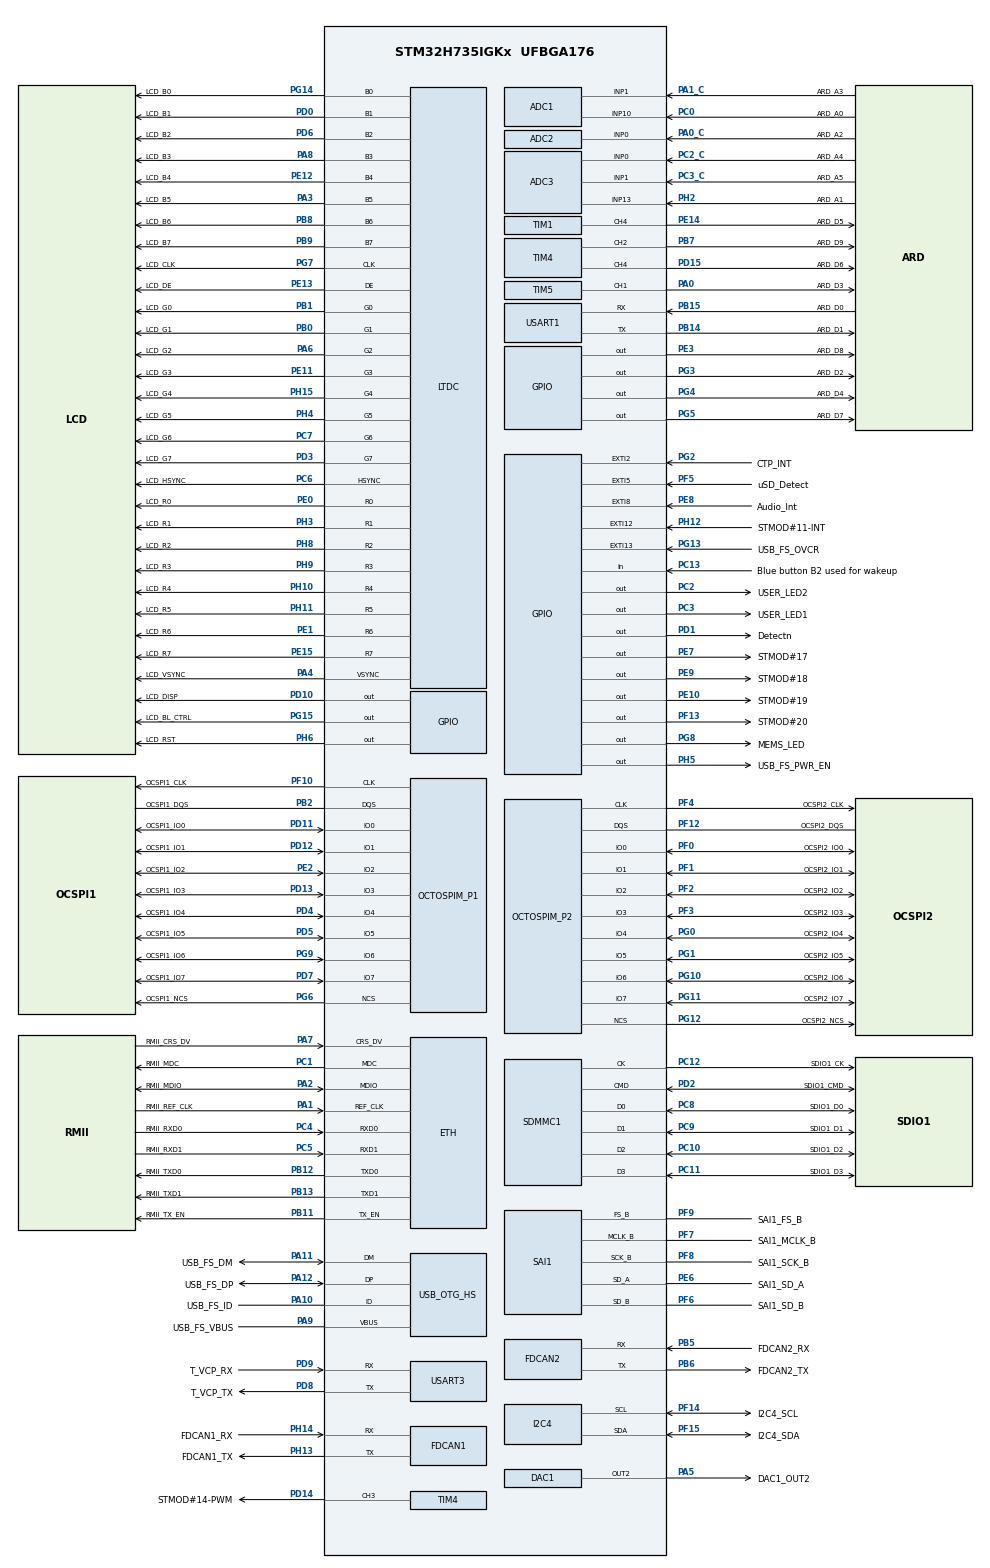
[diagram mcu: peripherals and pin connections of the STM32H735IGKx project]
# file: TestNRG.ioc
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ADC1.Channel-1\#ChannelRegularConversion=ADC_CHANNEL_1
ADC1.NbrOfConversionFlag=1
ADC1.OffsetNumber-1\#ChannelRegularConversion=ADC_OFFSET_NONE
ADC1.OffsetSignedSaturation-1\#ChannelRegularConversion=DISABLE
ADC1.Rank-1\#ChannelRegularConversion=1
ADC1.SamplingTime-1\#ChannelRegularConversion=ADC_SAMPLETIME_1CYCLE_5
ADC1.master=1
ADC2.Channel-0\#ChannelRegularConversion=ADC_CHANNEL_0
ADC2.NbrOfConversionFlag=1
ADC2.OffsetNumber-0\#ChannelRegularConversion=ADC_OFFSET_NONE
ADC2.OffsetSignedSaturation-0\#ChannelRegularConversion=DISABLE
ADC2.Rank-0\#ChannelRegularConversion=1
ADC2.SamplingTime-0\#ChannelRegularConversion=ADC_SAMPLETIME_1CYCLE_5
ADC3.Channel-2\#ChannelRegularConversion=ADC_CHANNEL_0
ADC3.NbrOfConversionFlag=1
ADC3.OffsetNumber-2\#ChannelRegularConversion=ADC_OFFSET_NONE
ADC3.OffsetSaturation-2\#ChannelRegularConversion=DISABLE
ADC3.OffsetSign-2\#ChannelRegularConversion=ADC3_OFFSET_SIGN_NEGATIVE
ADC3.OffsetSignedSaturation-2\#ChannelRegularConversion=DISABLE
ADC3.Rank-2\#ChannelRegularConversion=1
ADC3.SamplingTime-2\#ChannelRegularConversion=ADC3_SAMPLETIME_2CYCLES_5
DAC1.DAC_Channel-DAC_OUT2=DAC_CHANNEL_2
ETH.MediaInterface=HAL_ETH_RMII_MODE
FDCAN1.CalculateBaudRateNominal=1718750
FDCAN1.CalculateTimeBitNominal=581
FDCAN1.CalculateTimeQuantumNominal=116.36363636363636
FDCAN2.CalculateBaudRateNominal=1718750
FDCAN2.CalculateTimeBitNominal=581
FDCAN2.CalculateTimeQuantumNominal=116.36363636363636
I2C4.Timing=0x60404E72
Mcu.Family=STM32H7
Mcu.Name=STM32H735IGKx
Mcu.Package=UFBGA176
NVIC.PriorityGroup=NVIC_PRIORITYGROUP_4
PA0.GPIO_Label=ARD_D3
PA0.Signal=S_TIM5_CH1
PA0_C.GPIO_Label=ARD_A2
PA0_C.Signal=ADCx_INP0
PA1.GPIO_Label=RMII_REF_CLK
PA1.GPIO_Speed=GPIO_SPEED_FREQ_LOW
PA1.Mode=RMII
PA1.Signal=ETH_REF_CLK
PA10.GPIO_Label=USB_FS_ID
PA10.Mode=OTG/Dual-Role-Device-FS
PA10.Signal=USB_OTG_HS_ID
PA11.GPIO_Label=USB_FS_DM
PA11.Mode=OTG/Dual-Role-Device-FS
PA11.Signal=USB_OTG_HS_DM
PA12.GPIO_Label=USB_FS_DP
PA12.Mode=OTG/Dual-Role-Device-FS
PA12.Signal=USB_OTG_HS_DP
PA13(JTMS/SWDIO).GPIO_Label=JTMS
PA13(JTMS/SWDIO).Mode=JTAG_5_pins
PA13(JTMS/SWDIO).Signal=DEBUG_JTMS-SWDIO
PA14(JTCK/SWCLK).GPIO_Label=JTCK
PA14(JTCK/SWCLK).Mode=JTAG_5_pins
PA14(JTCK/SWCLK).Signal=DEBUG_JTCK-SWCLK
PA15(JTDI).GPIO_Label=JTDI
PA15(JTDI).Mode=JTAG_5_pins
PA15(JTDI).Signal=DEBUG_JTDI
PA1_C.GPIO_Label=ARD_A3
PA1_C.Signal=ADCx_INP1
PA2.GPIO_Label=RMII_MDIO
PA2.GPIO_Speed=GPIO_SPEED_FREQ_LOW
PA2.Mode=RMII
PA2.Signal=ETH_MDIO
PA3.GPIO_Label=LCD_B5
PA3.GPIO_Speed=GPIO_SPEED_FREQ_LOW
PA3.Mode=RGB888
PA3.Signal=LTDC_B5
PA4.GPIO_Label=LCD_VSYNC
PA4.GPIO_Speed=GPIO_SPEED_FREQ_LOW
PA4.Mode=RGB888
PA4.Signal=LTDC_VSYNC
PA5.GPIO_Label=DAC1_OUT2
PA5.Signal=COMP_DAC12_group
PA6.GPIO_Label=LCD_G2
PA6.GPIO_Speed=GPIO_SPEED_FREQ_LOW
PA6.Mode=RGB888
PA6.Signal=LTDC_G2
PA7.GPIO_Label=RMII_CRS_DV
PA7.GPIO_Speed=GPIO_SPEED_FREQ_LOW
PA7.Mode=RMII
PA7.Signal=ETH_CRS_DV
PA8.GPIO_Label=LCD_B3
PA8.GPIO_Speed=GPIO_SPEED_FREQ_LOW
PA8.Mode=RGB888
PA8.Signal=LTDC_B3
PA9.GPIO_Label=USB_FS_VBUS
PA9.Mode=Activate_VBUS_FS
PA9.Signal=USB_OTG_HS_VBUS
PB0.GPIO_Label=LCD_G1
PB0.GPIO_Speed=GPIO_SPEED_FREQ_LOW
PB0.Mode=RGB888
PB0.Signal=LTDC_G1
PB1.GPIO_Label=LCD_G0
PB1.GPIO_Speed=GPIO_SPEED_FREQ_LOW
PB1.Mode=RGB888
PB1.Signal=LTDC_G0
PB10.GPIO_Label=RMII_RX_ER
PB10.Signal=ETH_RX_ER
PB11.GPIO_Label=RMII_TX_EN
PB11.GPIO_Speed=GPIO_SPEED_FREQ_LOW
PB11.Mode=RMII
PB11.Signal=ETH_TX_EN
PB12.GPIO_Label=RMII_TXD0
PB12.GPIO_Speed=GPIO_SPEED_FREQ_LOW
PB12.Mode=RMII
PB12.Signal=ETH_TXD0
PB13.GPIO_Label=RMII_TXD1
PB13.GPIO_Speed=GPIO_SPEED_FREQ_LOW
PB13.Mode=RMII
PB13.Signal=ETH_TXD1
PB14.GPIO_Label=ARD_D1
PB14.GPIO_PuPd=GPIO_NOPULL
PB14.Mode=Asynchronous
PB14.Signal=USART1_TX
PB15.GPIO_Label=ARD_D0
PB15.GPIO_PuPd=GPIO_NOPULL
PB15.Mode=Asynchronous
PB15.Signal=USART1_RX
PB2.GPIO_Label=OCSPI1_DQS
PB2.Mode=OCTOSPI1_Port1_DQS
PB2.Signal=OCTOSPIM_P1_DQS
PB3(JTDO/TRACESWO).GPIO_Label=JTDO
PB3(JTDO/TRACESWO).Mode=JTAG_5_pins
PB3(JTDO/TRACESWO).Signal=DEBUG_JTDO-SWO
PB4(NJTRST).GPIO_Label=NJTRST
PB4(NJTRST).Mode=JTAG_5_pins
PB4(NJTRST).Signal=DEBUG_JTRST
PB5.GPIO_Label=FDCAN2_RX
PB5.Mode=FDCAN_Activate
PB5.Signal=FDCAN2_RX
PB6.GPIO_Label=FDCAN2_TX
PB6.Mode=FDCAN_Activate
PB6.Signal=FDCAN2_TX
PB7.GPIO_Label=ARD_D9
PB7.Signal=S_TIM4_CH2
PB8.GPIO_Label=LCD_B6
PB8.GPIO_Speed=GPIO_SPEED_FREQ_LOW
PB8.Mode=RGB888
PB8.Signal=LTDC_B6
PB9.GPIO_Label=LCD_B7
PB9.GPIO_Speed=GPIO_SPEED_FREQ_LOW
PB9.Mode=RGB888
PB9.Signal=LTDC_B7
PC0.GPIO_Label=ARD_A0
PC0.Signal=ADCx_INP10
PC1.GPIO_Label=RMII_MDC
PC1.GPIO_Speed=GPIO_SPEED_FREQ_LOW
PC1.Mode=RMII
PC1.Signal=ETH_MDC
PC10.GPIO_Label=SDIO1_D2
PC10.Mode=SD_4_bits_Wide_bus
PC10.Signal=SDMMC1_D2
PC11.GPIO_Label=SDIO1_D3
PC11.Mode=SD_4_bits_Wide_bus
PC11.Signal=SDMMC1_D3
PC12.GPIO_Label=SDIO1_CK
PC12.Mode=SD_4_bits_Wide_bus
PC12.Signal=SDMMC1_CK
PC13.GPIO_Label=Blue button B2 used for wakeup
PC13.Signal=GPIO_Input
PC14-OSC32_IN.Mode=LSE-External-Oscillator
PC14-OSC32_IN.Signal=RCC_OSC32_IN
PC15-OSC32_OUT.Mode=LSE-External-Oscillator
PC15-OSC32_OUT.Signal=RCC_OSC32_OUT
PC2.GPIO_Label=USER_LED2
PC2.Signal=GPIO_Output
PC2_C.GPIO_Label=ARD_A4
PC2_C.Mode=IN0-Single-Ended
PC2_C.Signal=ADC3_INP0
PC3.GPIO_Label=USER_LED1
PC3.Signal=GPIO_Output
PC3_C.GPIO_Label=ARD_A5
PC3_C.Mode=IN1-Single-Ended
PC3_C.Signal=ADC3_INP1
PC4.GPIO_Label=RMII_RXD0
PC4.GPIO_Speed=GPIO_SPEED_FREQ_LOW
PC4.Mode=RMII
PC4.Signal=ETH_RXD0
PC5.GPIO_Label=RMII_RXD1
PC5.GPIO_Speed=GPIO_SPEED_FREQ_LOW
PC5.Mode=RMII
PC5.Signal=ETH_RXD1
PC6.GPIO_Label=LCD_HSYNC
PC6.GPIO_Speed=GPIO_SPEED_FREQ_LOW
PC6.Mode=RGB888
PC6.Signal=LTDC_HSYNC
PC7.GPIO_Label=LCD_G6
PC7.GPIO_Speed=GPIO_SPEED_FREQ_LOW
PC7.Mode=RGB888
PC7.Signal=LTDC_G6
PC8.GPIO_Label=SDIO1_D0
PC8.Mode=SD_4_bits_Wide_bus
PC8.Signal=SDMMC1_D0
PC9.GPIO_Label=SDIO1_D1
PC9.Mode=SD_4_bits_Wide_bus
PC9.Signal=SDMMC1_D1
PD0.GPIO_Label=LCD_B1
PD0.GPIO_Speed=GPIO_SPEED_FREQ_LOW
PD0.Mode=RGB888
PD0.Signal=LTDC_B1
PD1.GPIO_Label=Detectn
PD1.GPIO_PuPd=GPIO_NOPULL
PD1.Signal=GPIO_Output
PD10.GPIO_Label=LCD_DISP
PD10.GPIO_Speed=GPIO_SPEED_FREQ_LOW
PD10.Signal=GPIO_Output
PD11.GPIO_Label=OCSPI1_IO0
PD11.Mode=OCTOSPI1_IOL_Port1L
PD11.Signal=OCTOSPIM_P1_IO0
PD12.GPIO_Label=OCSPI1_IO1
PD12.Mode=OCTOSPI1_IOL_Port1L
PD12.Signal=OCTOSPIM_P1_IO1
PD13.GPIO_Label=OCSPI1_IO3
PD13.Mode=OCTOSPI1_IOL_Port1L
PD13.Signal=OCTOSPIM_P1_IO3
PD14.GPIO_Label=STMOD\#14-PWM
PD14.Signal=S_TIM4_CH3
PD15.GPIO_Label=ARD_D6
PD15.Signal=S_TIM4_CH4
PD2.GPIO_Label=SDIO1_CMD
PD2.Mode=SD_4_bits_Wide_bus
PD2.Signal=SDMMC1_CMD
PD3.GPIO_Label=LCD_G7
PD3.GPIO_Speed=GPIO_SPEED_FREQ_LOW
PD3.Mode=RGB888
PD3.Signal=LTDC_G7
PD4.GPIO_Label=OCSPI1_IO4
PD4.Mode=OCTOSPI1_IOH_Port1H
PD4.Signal=OCTOSPIM_P1_IO4
PD5.GPIO_Label=OCSPI1_IO5
PD5.Mode=OCTOSPI1_IOH_Port1H
PD5.Signal=OCTOSPIM_P1_IO5
PD6.GPIO_Label=LCD_B2
PD6.GPIO_Speed=GPIO_SPEED_FREQ_LOW
PD6.Mode=RGB888
PD6.Signal=LTDC_B2
PD7.GPIO_Label=OCSPI1_IO7
PD7.Mode=OCTOSPI1_IOH_Port1H
PD7.Signal=OCTOSPIM_P1_IO7
PD8.GPIO_Label=T_VCP_TX
PD8.GPIO_PuPd=GPIO_NOPULL
PD8.Mode=Asynchronous
PD8.Signal=USART3_TX
PD9.GPIO_Label=T_VCP_RX
PD9.GPIO_PuPd=GPIO_NOPULL
PD9.Mode=Asynchronous
PD9.Signal=USART3_RX
PE0.GPIO_Label=LCD_R0
PE0.GPIO_Speed=GPIO_SPEED_FREQ_LOW
PE0.Mode=RGB888
PE0.Signal=LTDC_R0
PE1.GPIO_Label=LCD_R6
PE1.GPIO_Speed=GPIO_SPEED_FREQ_LOW
PE1.Mode=RGB888
PE1.Signal=LTDC_R6
PE10.GPIO_Label=STMOD\#19
PE10.Signal=GPIO_Output
PE11.GPIO_Label=LCD_G3
PE11.GPIO_Speed=GPIO_SPEED_FREQ_LOW
PE11.Mode=RGB888
PE11.Signal=LTDC_G3
PE12.GPIO_Label=LCD_B4
PE12.GPIO_Speed=GPIO_SPEED_FREQ_LOW
PE12.Mode=RGB888
PE12.Signal=LTDC_B4
PE13.GPIO_Label=LCD_DE
PE13.GPIO_Speed=GPIO_SPEED_FREQ_LOW
PE13.Mode=RGB888
PE13.Signal=LTDC_DE
PE14.GPIO_Label=ARD_D5
PE14.Signal=S_TIM1_CH4
PE15.GPIO_Label=LCD_R7
PE15.GPIO_Speed=GPIO_SPEED_FREQ_LOW
PE15.Mode=RGB888
PE15.Signal=LTDC_R7
PE2.GPIO_Label=OCSPI1_IO2
PE2.Mode=OCTOSPI1_IOL_Port1L
PE2.Signal=OCTOSPIM_P1_IO2
PE3.GPIO_Label=ARD_D8
PE3.Signal=GPIO_Output
PE4.GPIO_Label=SAI4_D2
PE4.Signal=SAI4_D2
PE5.GPIO_Label=SAI4_CK2
PE5.Signal=SAI4_CK2
PE6.GPIO_Label=SAI1_SD_A
PE6.Mode=SAI_A_SyncSlave
PE6.Signal=SAI1_SD_A
PE7.GPIO_Label=STMOD\#17
PE7.Signal=GPIO_Output
PE8.GPIO_Label=Audio_Int
PE8.Signal=GPXTI8
PE9.GPIO_Label=STMOD\#18
PE9.Signal=GPIO_Output
PF0.GPIO_Label=OCSPI2_IO0
PF0.Mode=OCTOSPI2_IOL_Port2L
PF0.Signal=OCTOSPIM_P2_IO0
PF1.GPIO_Label=OCSPI2_IO1
PF1.Mode=OCTOSPI2_IOL_Port2L
PF1.Signal=OCTOSPIM_P2_IO1
PF10.GPIO_Label=OCSPI1_CLK
PF10.Mode=O1_P1_CLK
PF10.Signal=OCTOSPIM_P1_CLK
PF11.GPIO_Label=SPI5_MOSI
PF11.Signal=SPI5_MOSI
PF12.GPIO_Label=OCSPI2_DQS
PF12.Mode=OCTOSPI2_Port2_DQS
PF12.Signal=OCTOSPIM_P2_DQS
PF13.GPIO_Label=STMOD\#20
PF13.Signal=GPIO_Output
PF14.GPIO_Label=I2C4_SCL
PF14.GPIO_Pu=GPIO_PULLUP
PF14.Mode=I2C
PF14.Signal=I2C4_SCL
PF15.GPIO_Label=I2C4_SDA
PF15.GPIO_Pu=GPIO_PULLUP
PF15.Mode=I2C
PF15.Signal=I2C4_SDA
PF2.GPIO_Label=OCSPI2_IO2
PF2.Mode=OCTOSPI2_IOL_Port2L
PF2.Signal=OCTOSPIM_P2_IO2
PF3.GPIO_Label=OCSPI2_IO3
PF3.Mode=OCTOSPI2_IOL_Port2L
PF3.Signal=OCTOSPIM_P2_IO3
PF4.GPIO_Label=OCSPI2_CLK
PF4.Mode=O2_P2_CLK
PF4.Signal=OCTOSPIM_P2_CLK
PF5.GPIO_Label=uSD_Detect
PF5.Signal=GPXTI5
PF6.GPIO_Label=SAI1_SD_B
PF6.Mode=SAI_B_MasterWithClock
PF6.Signal=SAI1_SD_B
PF7.GPIO_Label=SAI1_MCLK_B
PF7.Mode=SAI_B_MasterWithClock
PF7.Signal=SAI1_MCLK_B
PF8.GPIO_Label=SAI1_SCK_B
PF8.Mode=SAI_B_MasterWithClock
PF8.Signal=SAI1_SCK_B
PF9.GPIO_Label=SAI1_FS_B
PF9.Mode=SAI_B_MasterWithClock
PF9.Signal=SAI1_FS_B
PG0.GPIO_Label=OCSPI2_IO4
PG0.Mode=OCTOSPI2_IOH_Port2H
PG0.Signal=OCTOSPIM_P2_IO4
PG1.GPIO_Label=OCSPI2_IO5
PG1.Mode=OCTOSPI2_IOH_Port2H
PG1.Signal=OCTOSPIM_P2_IO5
PG10.GPIO_Label=OCSPI2_IO6
PG10.Mode=OCTOSPI2_IOH_Port2H
PG10.Signal=OCTOSPIM_P2_IO6
PG11.GPIO_Label=OCSPI2_IO7
PG11.Mode=OCTOSPI2_IOH_Port2H
PG11.Signal=OCTOSPIM_P2_IO7
PG12.GPIO_Label=OCSPI2_NCS
PG12.Mode=OCTOSPI2_Port2_NCS
PG12.Signal=OCTOSPIM_P2_NCS
PG13.GPIO_Label=USB_FS_OVCR
PG13.Signal=GPXTI13
PG14.GPIO_Label=LCD_B0
PG14.GPIO_Speed=GPIO_SPEED_FREQ_LOW
PG14.Mode=RGB888
PG14.Signal=LTDC_B0
PG15.GPIO_Label=LCD_BL_CTRL
PG15.GPIO_Speed=GPIO_SPEED_FREQ_LOW
PG15.Signal=GPIO_Output
PG2.GPIO_Label=CTP_INT
PG2.Signal=GPXTI2
PG3.GPIO_Label=ARD_D2
PG3.Signal=GPIO_Output
PG4.GPIO_Label=ARD_D4
PG4.Signal=GPIO_Output
PG5.GPIO_Label=ARD_D7
PG5.Signal=GPIO_Output
PG6.GPIO_Label=OCSPI1_NCS
PG6.Mode=OCTOSPI1_Port1_NCS
PG6.Signal=OCTOSPIM_P1_NCS
PG7.GPIO_Label=LCD_CLK
PG7.GPIO_Speed=GPIO_SPEED_FREQ_LOW
PG7.Mode=RGB888
PG7.Signal=LTDC_CLK
PG8.GPIO_Label=MEMS_LED
PG8.Signal=GPIO_Output
PG9.GPIO_Label=OCSPI1_IO6
PG9.Mode=OCTOSPI1_IOH_Port1H
PG9.Signal=OCTOSPIM_P1_IO6
PH0-OSC_IN.Mode=HSE-External-Oscillator
PH0-OSC_IN.Signal=RCC_OSC_IN
PH1-OSC_OUT.Mode=HSE-External-Oscillator
PH1-OSC_OUT.Signal=RCC_OSC_OUT
PH10.GPIO_Label=LCD_R4
PH10.GPIO_Speed=GPIO_SPEED_FREQ_LOW
PH10.Mode=RGB888
PH10.Signal=LTDC_R4
PH11.GPIO_Label=LCD_R5
PH11.GPIO_Speed=GPIO_SPEED_FREQ_LOW
PH11.Mode=RGB888
PH11.Signal=LTDC_R5
PH12.GPIO_Label=STMOD\#11-INT
PH12.Signal=GPXTI12
PH13.GPIO_Label=FDCAN1_TX
PH13.Mode=FDCAN_Activate
PH13.Signal=FDCAN1_TX
PH14.GPIO_Label=FDCAN1_RX
PH14.Mode=FDCAN_Activate
PH14.Signal=FDCAN1_RX
PH15.GPIO_Label=LCD_G4
PH15.GPIO_Speed=GPIO_SPEED_FREQ_LOW
PH15.Mode=RGB888
PH15.Signal=LTDC_G4
PH2.GPIO_Label=ARD_A1
PH2.Mode=IN13-Single-Ended
PH2.Signal=ADC3_INP13
PH3.GPIO_Label=LCD_R1
PH3.GPIO_Speed=GPIO_SPEED_FREQ_LOW
PH3.Mode=RGB888
PH3.Signal=LTDC_R1
PH4.GPIO_Label=LCD_G5
PH4.GPIO_Speed=GPIO_SPEED_FREQ_LOW
PH4.Mode=RGB888
PH4.Signal=LTDC_G5
PH5.GPIO_Label=USB_FS_PWR_EN
PH5.Signal=GPIO_Output
PH6.GPIO_Label=LCD_RST
PH6.GPIO_Speed=GPIO_SPEED_FREQ_LOW
PH6.Signal=GPIO_Output
PH7.GPIO_Label=SPI5_MISO
PH7.Signal=SPI5_MISO
PH8.GPIO_Label=LCD_R2
PH8.GPIO_Speed=GPIO_SPEED_FREQ_LOW
PH8.Mode=RGB888
PH8.Signal=LTDC_R2
PH9.GPIO_Label=LCD_R3
PH9.GPIO_Speed=GPIO_SPEED_FREQ_LOW
PH9.Mode=RGB888
PH9.Signal=LTDC_R3
ProjectManager.HeapSize=0x2000
ProjectManager.StackSize=0x4000
ProjectManager.TargetToolchain=CMake
RCC.ADCFreq_Value=80000000
RCC.APB1Freq_Value=137500000
RCC.APB2Freq_Value=137500000
RCC.APB3Freq_Value=137500000
RCC.APB4Freq_Value=137500000
RCC.CortexFreq_Value=550000000
RCC.D1PPRE=RCC_APB3_DIV2
RCC.D2PPRE1=RCC_APB1_DIV2
RCC.D2PPRE2=RCC_APB2_DIV2
RCC.D3PPRE=RCC_APB4_DIV2
RCC.DIVM1=5
RCC.DIVM2=5
RCC.DIVN1=110
RCC.DIVN2=80
RCC.DIVP1=1
RCC.DIVP2=5
RCC.DIVQ1=4
RCC.HCLKFreq_Value=275000000
RCC.HPRE=RCC_HCLK_DIV2
RCC.PLL2FRACN=0
RCC.PLL3FRACN=0
RCC.PLLFRACN=0
RCC.PLLSourceVirtual=RCC_PLLSOURCE_HSE
RCC.SYSCLKFreq_VALUE=550000000
RCC.SYSCLKSource=RCC_SYSCLKSOURCE_PLLCLK
RCC.USBCLockSelection=RCC_USBCLKSOURCE_HSI48
RCC.USBFreq_Value=48000000
SAI1.ErrorAudioFreq-SAI_B_MasterWithClock=39.87 %
SAI1.Instance-SAI_A_SyncSlave=SAI$Index_Block_A
SAI1.Instance-SAI_B_MasterWithClock=SAI$Index_Block_B
SAI1.MckOutput-SAI_B_MasterWithClock=SAI_MCK_OUTPUT_ENABLE
SAI1.RealAudioFreq-SAI_B_MasterWithClock=268.554 KHz
SAI1.VirtualMode-SAI_A_SyncSlave=VM_SLAVE
SAI1.VirtualMode-SAI_B_MasterWithClock=VM_MASTER
SH.ADCx_INP0.0=ADC1_INP0
SH.ADCx_INP0.1=ADC2_INP0,IN0-Single-Ended
SH.ADCx_INP1.0=ADC2_INP1
SH.ADCx_INP1.1=ADC1_INP1,IN1-Single-Ended
SH.ADCx_INP10.0=ADC1_INP10,IN10-Single-Ended
SH.COMP_DAC12_group.0=DAC1_OUT2,DAC_OUT2
SH.S_TIM1_CH4.0=TIM1_CH4,PWM Generation4 CH4
SH.S_TIM4_CH2.0=TIM4_CH2,PWM Generation2 CH2
SH.S_TIM4_CH3.0=TIM4_CH3,PWM Generation3 CH3
SH.S_TIM4_CH4.0=TIM4_CH4,PWM Generation4 CH4
SH.S_TIM5_CH1.0=TIM5_CH1,PWM Generation1 CH1
TIM1.Channel-PWM\ Generation4\ CH4=TIM_CHANNEL_4
TIM4.Channel-PWM\ Generation2\ CH2=TIM_CHANNEL_2
TIM4.Channel-PWM\ Generation3\ CH3=TIM_CHANNEL_3
TIM4.Channel-PWM\ Generation4\ CH4=TIM_CHANNEL_4
TIM5.Channel-PWM\ Generation1\ CH1=TIM_CHANNEL_1
USART1.VirtualMode-Asynchronous=VM_ASYNC
USART3.VirtualMode-Asynchronous=VM_ASYNC
VP_OCTOSPI1_VS_octo.Mode=octo_mode
VP_OCTOSPI2_VS_octo.Mode=hyperbus_mode
VP_RNG_VS_RNG.Mode=RNG_Activate
board=STM32H735G-DK

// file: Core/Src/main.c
/* USER CODE BEGIN Header */
/**
 ******************************************************************************
 * @file           : main.c
 * @brief          : Main program body
 ******************************************************************************
 * @attention
 *
 * Copyright (c) 2024 STMicroelectronics.
 * All rights reserved.
 *
 * This software is licensed under terms that can be found in the LICENSE file
 * in the root directory of this software component.
 * If no LICENSE file comes with this software, it is provided AS-IS.
 *
 ******************************************************************************
 */
/* USER CODE END Header */
#include "main.h"
#include "string.h"

/* USER CODE BEGIN PD */
#define NUM_OF_RND_VALUES (10)
/* USER CODE END PD */

#if defined(__ICCARM__) /*!< IAR Compiler */
#pragma location = 0x30000000
ETH_DMADescTypeDef DMARxDscrTab[ETH_RX_DESC_CNT]; /* Ethernet Rx DMA Descriptors */
#pragma location = 0x30000200
ETH_DMADescTypeDef DMATxDscrTab[ETH_TX_DESC_CNT]; /* Ethernet Tx DMA Descriptors */

#elif defined(__CC_ARM) /* MDK ARM Compiler */

__attribute__((at(0x30000000))) ETH_DMADescTypeDef DMARxDscrTab[ETH_RX_DESC_CNT]; /* Ethernet Rx DMA Descriptors */
__attribute__((at(0x30000200))) ETH_DMADescTypeDef DMATxDscrTab[ETH_TX_DESC_CNT]; /* Ethernet Tx DMA Descriptors */

#elif defined(__GNUC__) /* GNU Compiler */

ETH_DMADescTypeDef DMARxDscrTab[ETH_RX_DESC_CNT] __attribute__((section(".RxDecripSection"))); /* Ethernet Rx DMA Descriptors */
ETH_DMADescTypeDef DMATxDscrTab[ETH_TX_DESC_CNT] __attribute__((section(".TxDecripSection"))); /* Ethernet Tx DMA Descriptors */
#endif

ETH_TxPacketConfig TxConfig;

ADC_HandleTypeDef hadc1;
ADC_HandleTypeDef hadc2;
ADC_HandleTypeDef hadc3;

DAC_HandleTypeDef hdac1;

ETH_HandleTypeDef heth;

FDCAN_HandleTypeDef hfdcan1;
FDCAN_HandleTypeDef hfdcan2;

I2C_HandleTypeDef hi2c4;

LTDC_HandleTypeDef hltdc;

OSPI_HandleTypeDef hospi1;
OSPI_HandleTypeDef hospi2;

RNG_HandleTypeDef hrng;

SAI_HandleTypeDef hsai_BlockA1;
SAI_HandleTypeDef hsai_BlockB1;

SD_HandleTypeDef hsd1;

TIM_HandleTypeDef htim1;
TIM_HandleTypeDef htim4;
TIM_HandleTypeDef htim5;

UART_HandleTypeDef huart1;
UART_HandleTypeDef huart3;

/* USER CODE BEGIN PV */

/// @brief Stores the last 10 random values
static uint32_t rndValues[NUM_OF_RND_VALUES];

/// @brief Index counter within 'rndValues' array
static uint32_t rndCount = 0;

/* USER CODE END PV */

void SystemClock_Config(void);
void PeriphCommonClock_Config(void);
static void MX_GPIO_Init(void);
static void MX_ADC1_Init(void);
static void MX_ADC2_Init(void);
static void MX_ADC3_Init(void);
static void MX_DAC1_Init(void);
static void MX_ETH_Init(void);
static void MX_FDCAN1_Init(void);
static void MX_FDCAN2_Init(void);
static void MX_I2C4_Init(void);
static void MX_LTDC_Init(void);
static void MX_OCTOSPI1_Init(void);
static void MX_OCTOSPI2_Init(void);
static void MX_RNG_Init(void);
static void MX_SAI1_Init(void);
static void MX_SDMMC1_SD_Init(void);
static void MX_TIM1_Init(void);
static void MX_TIM4_Init(void);
static void MX_TIM5_Init(void);
static void MX_USART1_UART_Init(void);
static void MX_USART3_UART_Init(void);
static void MX_USB_OTG_HS_USB_Init(void);

int main(void)
{

    /* MCU Configuration--------------------------------------------------------*/

    /* Reset of all peripherals, Initializes the Flash interface and the Systick. */
    HAL_Init();

    /* Configure the system clock */
    SystemClock_Config();

    /* Configure the peripherals common clocks */
    PeriphCommonClock_Config();

    /* Initialize all configured peripherals */
    MX_GPIO_Init();
    MX_ADC1_Init();
    MX_ADC2_Init();
    MX_ADC3_Init();
    MX_DAC1_Init();
    MX_ETH_Init();
    MX_FDCAN1_Init();
    MX_FDCAN2_Init();
    MX_I2C4_Init();
    MX_LTDC_Init();
    MX_OCTOSPI1_Init();
    MX_OCTOSPI2_Init();
    MX_RNG_Init();
    MX_SAI1_Init();
    MX_SDMMC1_SD_Init();
    MX_TIM1_Init();
    MX_TIM4_Init();
    MX_TIM5_Init();
    MX_USART1_UART_Init();
    MX_USART3_UART_Init();
    MX_USB_OTG_HS_USB_Init();

    /* Infinite loop */
    /* USER CODE BEGIN WHILE */
    while (1)
    {
        HAL_RNG_GenerateRandomNumber(&hrng, &rndValues[rndCount]);
        rndCount++;
        rndCount %= NUM_OF_RND_VALUES;
        /* USER CODE END WHILE */

    }
}

void SystemClock_Config(void)
{
    RCC_OscInitTypeDef RCC_OscInitStruct = {0};
    RCC_ClkInitTypeDef RCC_ClkInitStruct = {0};

    /** Supply configuration update enable
     */
    HAL_PWREx_ConfigSupply(PWR_DIRECT_SMPS_SUPPLY);

    /** Configure the main internal regulator output voltage
     */
    __HAL_PWR_VOLTAGESCALING_CONFIG(PWR_REGULATOR_VOLTAGE_SCALE0);

    while (!__HAL_PWR_GET_FLAG(PWR_FLAG_VOSRDY))
    {
    }

    /** Initializes the RCC Oscillators according to the specified parameters
     * in the RCC_OscInitTypeDef structure.
     */
    RCC_OscInitStruct.OscillatorType = RCC_OSCILLATORTYPE_HSI48 | RCC_OSCILLATORTYPE_HSE;
    RCC_OscInitStruct.HSEState = RCC_HSE_ON;
    RCC_OscInitStruct.HSI48State = RCC_HSI48_ON;
    RCC_OscInitStruct.PLL.PLLState = RCC_PLL_ON;
    RCC_OscInitStruct.PLL.PLLSource = RCC_PLLSOURCE_HSE;
    RCC_OscInitStruct.PLL.PLLM = 5;
    RCC_OscInitStruct.PLL.PLLN = 110;
    RCC_OscInitStruct.PLL.PLLP = 1;
    RCC_OscInitStruct.PLL.PLLQ = 4;
    RCC_OscInitStruct.PLL.PLLR = 2;
    RCC_OscInitStruct.PLL.PLLRGE = RCC_PLL1VCIRANGE_2;
    RCC_OscInitStruct.PLL.PLLVCOSEL = RCC_PLL1VCOWIDE;
    RCC_OscInitStruct.PLL.PLLFRACN = 0;
    if (HAL_RCC_OscConfig(&RCC_OscInitStruct) != HAL_OK)
    {
        Error_Handler();
    }

    /** Initializes the CPU, AHB and APB buses clocks
     */
    RCC_ClkInitStruct.ClockType = RCC_CLOCKTYPE_HCLK | RCC_CLOCKTYPE_SYSCLK | RCC_CLOCKTYPE_PCLK1 | RCC_CLOCKTYPE_PCLK2 | RCC_CLOCKTYPE_D3PCLK1 | RCC_CLOCKTYPE_D1PCLK1;
    RCC_ClkInitStruct.SYSCLKSource = RCC_SYSCLKSOURCE_PLLCLK;
    RCC_ClkInitStruct.SYSCLKDivider = RCC_SYSCLK_DIV1;
    RCC_ClkInitStruct.AHBCLKDivider = RCC_HCLK_DIV2;
    RCC_ClkInitStruct.APB3CLKDivider = RCC_APB3_DIV2;
    RCC_ClkInitStruct.APB1CLKDivider = RCC_APB1_DIV2;
    RCC_ClkInitStruct.APB2CLKDivider = RCC_APB2_DIV2;
    RCC_ClkInitStruct.APB4CLKDivider = RCC_APB4_DIV2;

    if (HAL_RCC_ClockConfig(&RCC_ClkInitStruct, FLASH_LATENCY_3) != HAL_OK)
    {
        Error_Handler();
    }
}

void PeriphCommonClock_Config(void)
{
    RCC_PeriphCLKInitTypeDef PeriphClkInitStruct = {0};

    /** Initializes the peripherals clock
     */
    PeriphClkInitStruct.PeriphClockSelection = RCC_PERIPHCLK_ADC;
    PeriphClkInitStruct.PLL2.PLL2M = 5;
    PeriphClkInitStruct.PLL2.PLL2N = 80;
    PeriphClkInitStruct.PLL2.PLL2P = 5;
    PeriphClkInitStruct.PLL2.PLL2Q = 2;
    PeriphClkInitStruct.PLL2.PLL2R = 2;
    PeriphClkInitStruct.PLL2.PLL2RGE = RCC_PLL2VCIRANGE_2;
    PeriphClkInitStruct.PLL2.PLL2VCOSEL = RCC_PLL2VCOWIDE;
    PeriphClkInitStruct.PLL2.PLL2FRACN = 0;
    PeriphClkInitStruct.AdcClockSelection = RCC_ADCCLKSOURCE_PLL2;
    if (HAL_RCCEx_PeriphCLKConfig(&PeriphClkInitStruct) != HAL_OK)
    {
        Error_Handler();
    }
}

static void MX_ADC1_Init(void)
{

    ADC_MultiModeTypeDef multimode = {0};
    ADC_ChannelConfTypeDef sConfig = {0};

    /** Common config
     */
    hadc1.Instance = ADC1;
    hadc1.Init.ClockPrescaler = ADC_CLOCK_ASYNC_DIV1;
    hadc1.Init.Resolution = ADC_RESOLUTION_16B;
    hadc1.Init.ScanConvMode = ADC_SCAN_DISABLE;
    hadc1.Init.EOCSelection = ADC_EOC_SINGLE_CONV;
    hadc1.Init.LowPowerAutoWait = DISABLE;
    hadc1.Init.ContinuousConvMode = DISABLE;
    hadc1.Init.NbrOfConversion = 1;
    hadc1.Init.DiscontinuousConvMode = DISABLE;
    hadc1.Init.ExternalTrigConv = ADC_SOFTWARE_START;
    hadc1.Init.ExternalTrigConvEdge = ADC_EXTERNALTRIGCONVEDGE_NONE;
    hadc1.Init.ConversionDataManagement = ADC_CONVERSIONDATA_DR;
    hadc1.Init.Overrun = ADC_OVR_DATA_PRESERVED;
    hadc1.Init.LeftBitShift = ADC_LEFTBITSHIFT_NONE;
    hadc1.Init.OversamplingMode = DISABLE;
    if (HAL_ADC_Init(&hadc1) != HAL_OK)
    {
        Error_Handler();
    }

    /** Configure the ADC multi-mode
     */
    multimode.Mode = ADC_MODE_INDEPENDENT;
    if (HAL_ADCEx_MultiModeConfigChannel(&hadc1, &multimode) != HAL_OK)
    {
        Error_Handler();
    }

    /** Configure Regular Channel
     */
    sConfig.Channel = ADC_CHANNEL_1;
    sConfig.Rank = ADC_REGULAR_RANK_1;
    sConfig.SamplingTime = ADC_SAMPLETIME_1CYCLE_5;
    sConfig.SingleDiff = ADC_SINGLE_ENDED;
    sConfig.OffsetNumber = ADC_OFFSET_NONE;
    sConfig.Offset = 0;
    sConfig.OffsetSignedSaturation = DISABLE;
    if (HAL_ADC_ConfigChannel(&hadc1, &sConfig) != HAL_OK)
    {
        Error_Handler();
    }
}

static void MX_ADC2_Init(void)
{

    ADC_ChannelConfTypeDef sConfig = {0};

    /** Common config
     */
    hadc2.Instance = ADC2;
    hadc2.Init.ClockPrescaler = ADC_CLOCK_ASYNC_DIV1;
    hadc2.Init.Resolution = ADC_RESOLUTION_16B;
    hadc2.Init.ScanConvMode = ADC_SCAN_DISABLE;
    hadc2.Init.EOCSelection = ADC_EOC_SINGLE_CONV;
    hadc2.Init.LowPowerAutoWait = DISABLE;
    hadc2.Init.ContinuousConvMode = DISABLE;
    hadc2.Init.NbrOfConversion = 1;
    hadc2.Init.DiscontinuousConvMode = DISABLE;
    hadc2.Init.ExternalTrigConv = ADC_SOFTWARE_START;
    hadc2.Init.ExternalTrigConvEdge = ADC_EXTERNALTRIGCONVEDGE_NONE;
    hadc2.Init.ConversionDataManagement = ADC_CONVERSIONDATA_DR;
    hadc2.Init.Overrun = ADC_OVR_DATA_PRESERVED;
    hadc2.Init.LeftBitShift = ADC_LEFTBITSHIFT_NONE;
    hadc2.Init.OversamplingMode = DISABLE;
    if (HAL_ADC_Init(&hadc2) != HAL_OK)
    {
        Error_Handler();
    }

    /** Configure Regular Channel
     */
    sConfig.Channel = ADC_CHANNEL_0;
    sConfig.Rank = ADC_REGULAR_RANK_1;
    sConfig.SamplingTime = ADC_SAMPLETIME_1CYCLE_5;
    sConfig.SingleDiff = ADC_SINGLE_ENDED;
    sConfig.OffsetNumber = ADC_OFFSET_NONE;
    sConfig.Offset = 0;
    sConfig.OffsetSignedSaturation = DISABLE;
    if (HAL_ADC_ConfigChannel(&hadc2, &sConfig) != HAL_OK)
    {
        Error_Handler();
    }
}

static void MX_ADC3_Init(void)
{

    ADC_ChannelConfTypeDef sConfig = {0};

    /** Common config
     */
    hadc3.Instance = ADC3;
    hadc3.Init.ClockPrescaler = ADC_CLOCK_ASYNC_DIV1;
    hadc3.Init.Resolution = ADC_RESOLUTION_12B;
    hadc3.Init.DataAlign = ADC3_DATAALIGN_RIGHT;
    hadc3.Init.ScanConvMode = ADC_SCAN_DISABLE;
    hadc3.Init.EOCSelection = ADC_EOC_SINGLE_CONV;
    hadc3.Init.LowPowerAutoWait = DISABLE;
    hadc3.Init.ContinuousConvMode = DISABLE;
    hadc3.Init.NbrOfConversion = 1;
    hadc3.Init.DiscontinuousConvMode = DISABLE;
    hadc3.Init.ExternalTrigConv = ADC_SOFTWARE_START;
    hadc3.Init.ExternalTrigConvEdge = ADC_EXTERNALTRIGCONVEDGE_NONE;
    hadc3.Init.DMAContinuousRequests = DISABLE;
    hadc3.Init.SamplingMode = ADC_SAMPLING_MODE_NORMAL;
    hadc3.Init.ConversionDataManagement = ADC_CONVERSIONDATA_DR;
    hadc3.Init.Overrun = ADC_OVR_DATA_PRESERVED;
    hadc3.Init.LeftBitShift = ADC_LEFTBITSHIFT_NONE;
    hadc3.Init.OversamplingMode = DISABLE;
    if (HAL_ADC_Init(&hadc3) != HAL_OK)
    {
        Error_Handler();
    }

    /** Configure Regular Channel
     */
    sConfig.Channel = ADC_CHANNEL_0;
    sConfig.Rank = ADC_REGULAR_RANK_1;
    sConfig.SamplingTime = ADC3_SAMPLETIME_2CYCLES_5;
    sConfig.SingleDiff = ADC_SINGLE_ENDED;
    sConfig.OffsetNumber = ADC_OFFSET_NONE;
    sConfig.Offset = 0;
    sConfig.OffsetSignedSaturation = DISABLE;
    sConfig.OffsetSign = ADC3_OFFSET_SIGN_NEGATIVE;
    sConfig.OffsetSaturation = DISABLE;
    if (HAL_ADC_ConfigChannel(&hadc3, &sConfig) != HAL_OK)
    {
        Error_Handler();
    }
}

static void MX_DAC1_Init(void)
{

    DAC_ChannelConfTypeDef sConfig = {0};

    /** DAC Initialization
     */
    hdac1.Instance = DAC1;
    if (HAL_DAC_Init(&hdac1) != HAL_OK)
    {
        Error_Handler();
    }

    /** DAC channel OUT2 config
     */
    sConfig.DAC_SampleAndHold = DAC_SAMPLEANDHOLD_DISABLE;
    sConfig.DAC_Trigger = DAC_TRIGGER_NONE;
    sConfig.DAC_OutputBuffer = DAC_OUTPUTBUFFER_ENABLE;
    sConfig.DAC_ConnectOnChipPeripheral = DAC_CHIPCONNECT_DISABLE;
    sConfig.DAC_UserTrimming = DAC_TRIMMING_FACTORY;
    if (HAL_DAC_ConfigChannel(&hdac1, &sConfig, DAC_CHANNEL_2) != HAL_OK)
    {
        Error_Handler();
    }
}

static void MX_ETH_Init(void)
{

    static uint8_t MACAddr[6];

    heth.Instance = ETH;
    MACAddr[0] = 0x00;
    MACAddr[1] = 0x80;
    MACAddr[2] = 0xE1;
    MACAddr[3] = 0x00;
    MACAddr[4] = 0x00;
    MACAddr[5] = 0x00;
    heth.Init.MACAddr = &MACAddr[0];
    heth.Init.MediaInterface = HAL_ETH_RMII_MODE;
    heth.Init.TxDesc = DMATxDscrTab;
    heth.Init.RxDesc = DMARxDscrTab;
    heth.Init.RxBuffLen = 1524;

    if (HAL_ETH_Init(&heth) != HAL_OK)
    {
        Error_Handler();
    }

    memset(&TxConfig, 0, sizeof(ETH_TxPacketConfig));
    TxConfig.Attributes = ETH_TX_PACKETS_FEATURES_CSUM | ETH_TX_PACKETS_FEATURES_CRCPAD;
    TxConfig.ChecksumCtrl = ETH_CHECKSUM_IPHDR_PAYLOAD_INSERT_PHDR_CALC;
    TxConfig.CRCPadCtrl = ETH_CRC_PAD_INSERT;
}

static void MX_FDCAN1_Init(void)
{

    hfdcan1.Instance = FDCAN1;
    hfdcan1.Init.FrameFormat = FDCAN_FRAME_CLASSIC;
    hfdcan1.Init.Mode = FDCAN_MODE_NORMAL;
    hfdcan1.Init.AutoRetransmission = DISABLE;
    hfdcan1.Init.TransmitPause = DISABLE;
    hfdcan1.Init.ProtocolException = DISABLE;
    hfdcan1.Init.NominalPrescaler = 16;
    hfdcan1.Init.NominalSyncJumpWidth = 1;
    hfdcan1.Init.NominalTimeSeg1 = 2;
    hfdcan1.Init.NominalTimeSeg2 = 2;
    hfdcan1.Init.DataPrescaler = 1;
    hfdcan1.Init.DataSyncJumpWidth = 1;
    hfdcan1.Init.DataTimeSeg1 = 1;
    hfdcan1.Init.DataTimeSeg2 = 1;
    hfdcan1.Init.MessageRAMOffset = 0;
    hfdcan1.Init.StdFiltersNbr = 0;
    hfdcan1.Init.ExtFiltersNbr = 0;
    hfdcan1.Init.RxFifo0ElmtsNbr = 0;
    hfdcan1.Init.RxFifo0ElmtSize = FDCAN_DATA_BYTES_8;
    hfdcan1.Init.RxFifo1ElmtsNbr = 0;
    hfdcan1.Init.RxFifo1ElmtSize = FDCAN_DATA_BYTES_8;
    hfdcan1.Init.RxBuffersNbr = 0;
    hfdcan1.Init.RxBufferSize = FDCAN_DATA_BYTES_8;
    hfdcan1.Init.TxEventsNbr = 0;
    hfdcan1.Init.TxBuffersNbr = 0;
    hfdcan1.Init.TxFifoQueueElmtsNbr = 0;
    hfdcan1.Init.TxFifoQueueMode = FDCAN_TX_FIFO_OPERATION;
    hfdcan1.Init.TxElmtSize = FDCAN_DATA_BYTES_8;
    if (HAL_FDCAN_Init(&hfdcan1) != HAL_OK)
    {
        Error_Handler();
    }
}

static void MX_FDCAN2_Init(void)
{

    hfdcan2.Instance = FDCAN2;
    hfdcan2.Init.FrameFormat = FDCAN_FRAME_CLASSIC;
    hfdcan2.Init.Mode = FDCAN_MODE_NORMAL;
    hfdcan2.Init.AutoRetransmission = DISABLE;
    hfdcan2.Init.TransmitPause = DISABLE;
    hfdcan2.Init.ProtocolException = DISABLE;
    hfdcan2.Init.NominalPrescaler = 16;
    hfdcan2.Init.NominalSyncJumpWidth = 1;
    hfdcan2.Init.NominalTimeSeg1 = 2;
    hfdcan2.Init.NominalTimeSeg2 = 2;
    hfdcan2.Init.DataPrescaler = 1;
    hfdcan2.Init.DataSyncJumpWidth = 1;
    hfdcan2.Init.DataTimeSeg1 = 1;
    hfdcan2.Init.DataTimeSeg2 = 1;
    hfdcan2.Init.MessageRAMOffset = 0;
    hfdcan2.Init.StdFiltersNbr = 0;
    hfdcan2.Init.ExtFiltersNbr = 0;
    hfdcan2.Init.RxFifo0ElmtsNbr = 0;
    hfdcan2.Init.RxFifo0ElmtSize = FDCAN_DATA_BYTES_8;
    hfdcan2.Init.RxFifo1ElmtsNbr = 0;
    hfdcan2.Init.RxFifo1ElmtSize = FDCAN_DATA_BYTES_8;
    hfdcan2.Init.RxBuffersNbr = 0;
    hfdcan2.Init.RxBufferSize = FDCAN_DATA_BYTES_8;
    hfdcan2.Init.TxEventsNbr = 0;
    hfdcan2.Init.TxBuffersNbr = 0;
    hfdcan2.Init.TxFifoQueueElmtsNbr = 0;
    hfdcan2.Init.TxFifoQueueMode = FDCAN_TX_FIFO_OPERATION;
    hfdcan2.Init.TxElmtSize = FDCAN_DATA_BYTES_8;
    if (HAL_FDCAN_Init(&hfdcan2) != HAL_OK)
    {
        Error_Handler();
    }
}

static void MX_I2C4_Init(void)
{

    hi2c4.Instance = I2C4;
    hi2c4.Init.Timing = 0x60404E72;
    hi2c4.Init.OwnAddress1 = 0;
    hi2c4.Init.AddressingMode = I2C_ADDRESSINGMODE_7BIT;
    hi2c4.Init.DualAddressMode = I2C_DUALADDRESS_DISABLE;
    hi2c4.Init.OwnAddress2 = 0;
    hi2c4.Init.OwnAddress2Masks = I2C_OA2_NOMASK;
    hi2c4.Init.GeneralCallMode = I2C_GENERALCALL_DISABLE;
    hi2c4.Init.NoStretchMode = I2C_NOSTRETCH_DISABLE;
    if (HAL_I2C_Init(&hi2c4) != HAL_OK)
    {
        Error_Handler();
    }

    /** Configure Analogue filter
     */
    if (HAL_I2CEx_ConfigAnalogFilter(&hi2c4, I2C_ANALOGFILTER_ENABLE) != HAL_OK)
    {
        Error_Handler();
    }

    /** Configure Digital filter
     */
    if (HAL_I2CEx_ConfigDigitalFilter(&hi2c4, 0) != HAL_OK)
    {
        Error_Handler();
    }
}

static void MX_LTDC_Init(void)
{

    LTDC_LayerCfgTypeDef pLayerCfg = {0};
    LTDC_LayerCfgTypeDef pLayerCfg1 = {0};

    hltdc.Instance = LTDC;
    hltdc.Init.HSPolarity = LTDC_HSPOLARITY_AL;
    hltdc.Init.VSPolarity = LTDC_VSPOLARITY_AL;
    hltdc.Init.DEPolarity = LTDC_DEPOLARITY_AL;
    hltdc.Init.PCPolarity = LTDC_PCPOLARITY_IPC;
    hltdc.Init.HorizontalSync = 7;
    hltdc.Init.VerticalSync = 3;
    hltdc.Init.AccumulatedHBP = 14;
    hltdc.Init.AccumulatedVBP = 5;
    hltdc.Init.AccumulatedActiveW = 654;
    hltdc.Init.AccumulatedActiveH = 485;
    hltdc.Init.TotalWidth = 660;
    hltdc.Init.TotalHeigh = 487;
    hltdc.Init.Backcolor.Blue = 0;
    hltdc.Init.Backcolor.Green = 0;
    hltdc.Init.Backcolor.Red = 0;
    if (HAL_LTDC_Init(&hltdc) != HAL_OK)
    {
        Error_Handler();
    }
    pLayerCfg.WindowX0 = 0;
    pLayerCfg.WindowX1 = 0;
    pLayerCfg.WindowY0 = 0;
    pLayerCfg.WindowY1 = 0;
    pLayerCfg.PixelFormat = LTDC_PIXEL_FORMAT_ARGB8888;
    pLayerCfg.Alpha = 0;
    pLayerCfg.Alpha0 = 0;
    pLayerCfg.BlendingFactor1 = LTDC_BLENDING_FACTOR1_CA;
    pLayerCfg.BlendingFactor2 = LTDC_BLENDING_FACTOR2_CA;
    pLayerCfg.FBStartAdress = 0;
    pLayerCfg.ImageWidth = 0;
    pLayerCfg.ImageHeight = 0;
    pLayerCfg.Backcolor.Blue = 0;
    pLayerCfg.Backcolor.Green = 0;
    pLayerCfg.Backcolor.Red = 0;
    if (HAL_LTDC_ConfigLayer(&hltdc, &pLayerCfg, 0) != HAL_OK)
    {
        Error_Handler();
    }
    pLayerCfg1.WindowX0 = 0;
    pLayerCfg1.WindowX1 = 0;
    pLayerCfg1.WindowY0 = 0;
    pLayerCfg1.WindowY1 = 0;
    pLayerCfg1.PixelFormat = LTDC_PIXEL_FORMAT_ARGB8888;
    pLayerCfg1.Alpha = 0;
    pLayerCfg1.Alpha0 = 0;
    pLayerCfg1.BlendingFactor1 = LTDC_BLENDING_FACTOR1_CA;
    pLayerCfg1.BlendingFactor2 = LTDC_BLENDING_FACTOR2_CA;
    pLayerCfg1.FBStartAdress = 0;
    pLayerCfg1.ImageWidth = 0;
    pLayerCfg1.ImageHeight = 0;
    pLayerCfg1.Backcolor.Blue = 0;
    pLayerCfg1.Backcolor.Green = 0;
    pLayerCfg1.Backcolor.Red = 0;
    if (HAL_LTDC_ConfigLayer(&hltdc, &pLayerCfg1, 1) != HAL_OK)
    {
        Error_Handler();
    }
}

static void MX_OCTOSPI1_Init(void)
{

    OSPIM_CfgTypeDef sOspiManagerCfg = {0};

    /* OCTOSPI1 parameter configuration*/
    hospi1.Instance = OCTOSPI1;
    hospi1.Init.FifoThreshold = 1;
    hospi1.Init.DualQuad = HAL_OSPI_DUALQUAD_DISABLE;
    hospi1.Init.MemoryType = HAL_OSPI_MEMTYPE_MICRON;
    hospi1.Init.DeviceSize = 32;
    hospi1.Init.ChipSelectHighTime = 1;
    hospi1.Init.FreeRunningClock = HAL_OSPI_FREERUNCLK_DISABLE;
    hospi1.Init.ClockMode = HAL_OSPI_CLOCK_MODE_0;
    hospi1.Init.WrapSize = HAL_OSPI_WRAP_NOT_SUPPORTED;
    hospi1.Init.ClockPrescaler = 1;
    hospi1.Init.SampleShifting = HAL_OSPI_SAMPLE_SHIFTING_NONE;
    hospi1.Init.DelayHoldQuarterCycle = HAL_OSPI_DHQC_DISABLE;
    hospi1.Init.ChipSelectBoundary = 0;
    hospi1.Init.DelayBlockBypass = HAL_OSPI_DELAY_BLOCK_BYPASSED;
    hospi1.Init.MaxTran = 0;
    hospi1.Init.Refresh = 0;
    if (HAL_OSPI_Init(&hospi1) != HAL_OK)
    {
        Error_Handler();
    }
    sOspiManagerCfg.ClkPort = 1;
    sOspiManagerCfg.DQSPort = 1;
    sOspiManagerCfg.NCSPort = 1;
    sOspiManagerCfg.IOLowPort = HAL_OSPIM_IOPORT_1_LOW;
    sOspiManagerCfg.IOHighPort = HAL_OSPIM_IOPORT_1_HIGH;
    if (HAL_OSPIM_Config(&hospi1, &sOspiManagerCfg, HAL_OSPI_TIMEOUT_DEFAULT_VALUE) != HAL_OK)
    {
        Error_Handler();
    }
}

static void MX_OCTOSPI2_Init(void)
{

    OSPIM_CfgTypeDef sOspiManagerCfg = {0};
    OSPI_HyperbusCfgTypeDef sHyperBusCfg = {0};

    /* OCTOSPI2 parameter configuration*/
    hospi2.Instance = OCTOSPI2;
    hospi2.Init.FifoThreshold = 1;
    hospi2.Init.DualQuad = HAL_OSPI_DUALQUAD_DISABLE;
    hospi2.Init.MemoryType = HAL_OSPI_MEMTYPE_HYPERBUS;
    hospi2.Init.DeviceSize = 32;
    hospi2.Init.ChipSelectHighTime = 1;
    hospi2.Init.FreeRunningClock = HAL_OSPI_FREERUNCLK_DISABLE;
    hospi2.Init.ClockMode = HAL_OSPI_CLOCK_MODE_0;
    hospi2.Init.WrapSize = HAL_OSPI_WRAP_NOT_SUPPORTED;
    hospi2.Init.ClockPrescaler = 1;
    hospi2.Init.SampleShifting = HAL_OSPI_SAMPLE_SHIFTING_NONE;
    hospi2.Init.DelayHoldQuarterCycle = HAL_OSPI_DHQC_DISABLE;
    hospi2.Init.ChipSelectBoundary = 0;
    hospi2.Init.DelayBlockBypass = HAL_OSPI_DELAY_BLOCK_BYPASSED;
    hospi2.Init.MaxTran = 0;
    hospi2.Init.Refresh = 0;
    if (HAL_OSPI_Init(&hospi2) != HAL_OK)
    {
        Error_Handler();
    }
    sOspiManagerCfg.ClkPort = 2;
    sOspiManagerCfg.DQSPort = 2;
    sOspiManagerCfg.NCSPort = 2;
    sOspiManagerCfg.IOLowPort = HAL_OSPIM_IOPORT_2_LOW;
    sOspiManagerCfg.IOHighPort = HAL_OSPIM_IOPORT_2_HIGH;
    if (HAL_OSPIM_Config(&hospi2, &sOspiManagerCfg, HAL_OSPI_TIMEOUT_DEFAULT_VALUE) != HAL_OK)
    {
        Error_Handler();
    }
    sHyperBusCfg.RWRecoveryTime = 0;
    sHyperBusCfg.AccessTime = 0;
    sHyperBusCfg.WriteZeroLatency = HAL_OSPI_NO_LATENCY_ON_WRITE;
    sHyperBusCfg.LatencyMode = HAL_OSPI_VARIABLE_LATENCY;
    if (HAL_OSPI_HyperbusCfg(&hospi2, &sHyperBusCfg, HAL_OSPI_TIMEOUT_DEFAULT_VALUE) != HAL_OK)
    {
        Error_Handler();
    }
}

static void MX_RNG_Init(void)
{

    hrng.Instance = RNG;
    hrng.Init.ClockErrorDetection = RNG_CED_ENABLE;
    if (HAL_RNG_Init(&hrng) != HAL_OK)
    {
        Error_Handler();
    }
}

static void MX_SAI1_Init(void)
{

    hsai_BlockA1.Instance = SAI1_Block_A;
    hsai_BlockA1.Init.Protocol = SAI_FREE_PROTOCOL;
    hsai_BlockA1.Init.AudioMode = SAI_MODESLAVE_RX;
    hsai_BlockA1.Init.DataSize = SAI_DATASIZE_8;
    hsai_BlockA1.Init.FirstBit = SAI_FIRSTBIT_MSB;
    hsai_BlockA1.Init.ClockStrobing = SAI_CLOCKSTROBING_FALLINGEDGE;
    hsai_BlockA1.Init.Synchro = SAI_SYNCHRONOUS;
    hsai_BlockA1.Init.OutputDrive = SAI_OUTPUTDRIVE_DISABLE;
    hsai_BlockA1.Init.FIFOThreshold = SAI_FIFOTHRESHOLD_EMPTY;
    hsai_BlockA1.Init.SynchroExt = SAI_SYNCEXT_DISABLE;
    hsai_BlockA1.Init.MonoStereoMode = SAI_STEREOMODE;
    hsai_BlockA1.Init.CompandingMode = SAI_NOCOMPANDING;
    hsai_BlockA1.Init.TriState = SAI_OUTPUT_NOTRELEASED;
    hsai_BlockA1.Init.PdmInit.Activation = DISABLE;
    hsai_BlockA1.Init.PdmInit.MicPairsNbr = 0;
    hsai_BlockA1.Init.PdmInit.ClockEnable = SAI_PDM_CLOCK1_ENABLE;
    hsai_BlockA1.FrameInit.FrameLength = 8;
    hsai_BlockA1.FrameInit.ActiveFrameLength = 1;
    hsai_BlockA1.FrameInit.FSDefinition = SAI_FS_STARTFRAME;
    hsai_BlockA1.FrameInit.FSPolarity = SAI_FS_ACTIVE_LOW;
    hsai_BlockA1.FrameInit.FSOffset = SAI_FS_FIRSTBIT;
    hsai_BlockA1.SlotInit.FirstBitOffset = 0;
    hsai_BlockA1.SlotInit.SlotSize = SAI_SLOTSIZE_DATASIZE;
    hsai_BlockA1.SlotInit.SlotNumber = 1;
    hsai_BlockA1.SlotInit.SlotActive = 0x00000000;
    if (HAL_SAI_Init(&hsai_BlockA1) != HAL_OK)
    {
        Error_Handler();
    }
    hsai_BlockB1.Instance = SAI1_Block_B;
    hsai_BlockB1.Init.Protocol = SAI_FREE_PROTOCOL;
    hsai_BlockB1.Init.AudioMode = SAI_MODEMASTER_TX;
    hsai_BlockB1.Init.DataSize = SAI_DATASIZE_8;
    hsai_BlockB1.Init.FirstBit = SAI_FIRSTBIT_MSB;
    hsai_BlockB1.Init.ClockStrobing = SAI_CLOCKSTROBING_FALLINGEDGE;
    hsai_BlockB1.Init.Synchro = SAI_ASYNCHRONOUS;
    hsai_BlockB1.Init.OutputDrive = SAI_OUTPUTDRIVE_DISABLE;
    hsai_BlockB1.Init.NoDivider = SAI_MASTERDIVIDER_ENABLE;
    hsai_BlockB1.Init.FIFOThreshold = SAI_FIFOTHRESHOLD_EMPTY;
    hsai_BlockB1.Init.AudioFrequency = SAI_AUDIO_FREQUENCY_192K;
    hsai_BlockB1.Init.SynchroExt = SAI_SYNCEXT_DISABLE;
    hsai_BlockB1.Init.MonoStereoMode = SAI_STEREOMODE;
    hsai_BlockB1.Init.CompandingMode = SAI_NOCOMPANDING;
    hsai_BlockB1.Init.TriState = SAI_OUTPUT_NOTRELEASED;
    hsai_BlockB1.Init.PdmInit.Activation = DISABLE;
    hsai_BlockB1.Init.PdmInit.MicPairsNbr = 0;
    hsai_BlockB1.Init.PdmInit.ClockEnable = SAI_PDM_CLOCK1_ENABLE;
    hsai_BlockB1.FrameInit.FrameLength = 8;
    hsai_BlockB1.FrameInit.ActiveFrameLength = 1;
    hsai_BlockB1.FrameInit.FSDefinition = SAI_FS_STARTFRAME;
    hsai_BlockB1.FrameInit.FSPolarity = SAI_FS_ACTIVE_LOW;
    hsai_BlockB1.FrameInit.FSOffset = SAI_FS_FIRSTBIT;
    hsai_BlockB1.SlotInit.FirstBitOffset = 0;
    hsai_BlockB1.SlotInit.SlotSize = SAI_SLOTSIZE_DATASIZE;
    hsai_BlockB1.SlotInit.SlotNumber = 1;
    hsai_BlockB1.SlotInit.SlotActive = 0x00000000;
    if (HAL_SAI_Init(&hsai_BlockB1) != HAL_OK)
    {
        Error_Handler();
    }
}

static void MX_SDMMC1_SD_Init(void)
{

    hsd1.Instance = SDMMC1;
    hsd1.Init.ClockEdge = SDMMC_CLOCK_EDGE_RISING;
    hsd1.Init.ClockPowerSave = SDMMC_CLOCK_POWER_SAVE_DISABLE;
    hsd1.Init.BusWide = SDMMC_BUS_WIDE_4B;
    hsd1.Init.HardwareFlowControl = SDMMC_HARDWARE_FLOW_CONTROL_DISABLE;
    hsd1.Init.ClockDiv = 0;
    if (HAL_SD_Init(&hsd1) != HAL_OK)
    {
        Error_Handler();
    }
}

static void MX_TIM1_Init(void)
{

    TIM_MasterConfigTypeDef sMasterConfig = {0};
    TIM_OC_InitTypeDef sConfigOC = {0};
    TIM_BreakDeadTimeConfigTypeDef sBreakDeadTimeConfig = {0};

    htim1.Instance = TIM1;
    htim1.Init.Prescaler = 0;
    htim1.Init.CounterMode = TIM_COUNTERMODE_UP;
    htim1.Init.Period = 65535;
    htim1.Init.ClockDivision = TIM_CLOCKDIVISION_DIV1;
    htim1.Init.RepetitionCounter = 0;
    htim1.Init.AutoReloadPreload = TIM_AUTORELOAD_PRELOAD_DISABLE;
    if (HAL_TIM_PWM_Init(&htim1) != HAL_OK)
    {
        Error_Handler();
    }
    sMasterConfig.MasterOutputTrigger = TIM_TRGO_RESET;
    sMasterConfig.MasterOutputTrigger2 = TIM_TRGO2_RESET;
    sMasterConfig.MasterSlaveMode = TIM_MASTERSLAVEMODE_DISABLE;
    if (HAL_TIMEx_MasterConfigSynchronization(&htim1, &sMasterConfig) != HAL_OK)
    {
        Error_Handler();
    }
    sConfigOC.OCMode = TIM_OCMODE_PWM1;
    sConfigOC.Pulse = 0;
    sConfigOC.OCPolarity = TIM_OCPOLARITY_HIGH;
    sConfigOC.OCFastMode = TIM_OCFAST_DISABLE;
    sConfigOC.OCIdleState = TIM_OCIDLESTATE_RESET;
    sConfigOC.OCNIdleState = TIM_OCNIDLESTATE_RESET;
    if (HAL_TIM_PWM_ConfigChannel(&htim1, &sConfigOC, TIM_CHANNEL_4) != HAL_OK)
    {
        Error_Handler();
    }
    sBreakDeadTimeConfig.OffStateRunMode = TIM_OSSR_DISABLE;
    sBreakDeadTimeConfig.OffStateIDLEMode = TIM_OSSI_DISABLE;
    sBreakDeadTimeConfig.LockLevel = TIM_LOCKLEVEL_OFF;
    sBreakDeadTimeConfig.DeadTime = 0;
    sBreakDeadTimeConfig.BreakState = TIM_BREAK_DISABLE;
    sBreakDeadTimeConfig.BreakPolarity = TIM_BREAKPOLARITY_HIGH;
    sBreakDeadTimeConfig.BreakFilter = 0;
    sBreakDeadTimeConfig.Break2State = TIM_BREAK2_DISABLE;
    sBreakDeadTimeConfig.Break2Polarity = TIM_BREAK2POLARITY_HIGH;
    sBreakDeadTimeConfig.Break2Filter = 0;
    sBreakDeadTimeConfig.AutomaticOutput = TIM_AUTOMATICOUTPUT_DISABLE;
    if (HAL_TIMEx_ConfigBreakDeadTime(&htim1, &sBreakDeadTimeConfig) != HAL_OK)
    {
        Error_Handler();
    }
    HAL_TIM_MspPostInit(&htim1);
}

static void MX_TIM4_Init(void)
{

    TIM_MasterConfigTypeDef sMasterConfig = {0};
    TIM_OC_InitTypeDef sConfigOC = {0};

    htim4.Instance = TIM4;
    htim4.Init.Prescaler = 0;
    htim4.Init.CounterMode = TIM_COUNTERMODE_UP;
    htim4.Init.Period = 65535;
    htim4.Init.ClockDivision = TIM_CLOCKDIVISION_DIV1;
    htim4.Init.AutoReloadPreload = TIM_AUTORELOAD_PRELOAD_DISABLE;
    if (HAL_TIM_PWM_Init(&htim4) != HAL_OK)
    {
        Error_Handler();
    }
    sMasterConfig.MasterOutputTrigger = TIM_TRGO_RESET;
    sMasterConfig.MasterSlaveMode = TIM_MASTERSLAVEMODE_DISABLE;
    if (HAL_TIMEx_MasterConfigSynchronization(&htim4, &sMasterConfig) != HAL_OK)
    {
        Error_Handler();
    }
    sConfigOC.OCMode = TIM_OCMODE_PWM1;
    sConfigOC.Pulse = 0;
    sConfigOC.OCPolarity = TIM_OCPOLARITY_HIGH;
    sConfigOC.OCFastMode = TIM_OCFAST_DISABLE;
    if (HAL_TIM_PWM_ConfigChannel(&htim4, &sConfigOC, TIM_CHANNEL_2) != HAL_OK)
    {
        Error_Handler();
    }
    if (HAL_TIM_PWM_ConfigChannel(&htim4, &sConfigOC, TIM_CHANNEL_3) != HAL_OK)
    {
        Error_Handler();
    }
    if (HAL_TIM_PWM_ConfigChannel(&htim4, &sConfigOC, TIM_CHANNEL_4) != HAL_OK)
    {
        Error_Handler();
    }
    HAL_TIM_MspPostInit(&htim4);
}

static void MX_TIM5_Init(void)
{

    TIM_MasterConfigTypeDef sMasterConfig = {0};
    TIM_OC_InitTypeDef sConfigOC = {0};

    htim5.Instance = TIM5;
    htim5.Init.Prescaler = 0;
    htim5.Init.CounterMode = TIM_COUNTERMODE_UP;
    htim5.Init.Period = 4294967295;
    htim5.Init.ClockDivision = TIM_CLOCKDIVISION_DIV1;
    htim5.Init.AutoReloadPreload = TIM_AUTORELOAD_PRELOAD_DISABLE;
    if (HAL_TIM_PWM_Init(&htim5) != HAL_OK)
    {
        Error_Handler();
    }
    sMasterConfig.MasterOutputTrigger = TIM_TRGO_RESET;
    sMasterConfig.MasterSlaveMode = TIM_MASTERSLAVEMODE_DISABLE;
    if (HAL_TIMEx_MasterConfigSynchronization(&htim5, &sMasterConfig) != HAL_OK)
    {
        Error_Handler();
    }
    sConfigOC.OCMode = TIM_OCMODE_PWM1;
    sConfigOC.Pulse = 0;
    sConfigOC.OCPolarity = TIM_OCPOLARITY_HIGH;
    sConfigOC.OCFastMode = TIM_OCFAST_DISABLE;
    if (HAL_TIM_PWM_ConfigChannel(&htim5, &sConfigOC, TIM_CHANNEL_1) != HAL_OK)
    {
        Error_Handler();
    }
    HAL_TIM_MspPostInit(&htim5);
}

static void MX_USART1_UART_Init(void)
{

    huart1.Instance = USART1;
    huart1.Init.BaudRate = 115200;
    huart1.Init.WordLength = UART_WORDLENGTH_8B;
    huart1.Init.StopBits = UART_STOPBITS_1;
    huart1.Init.Parity = UART_PARITY_NONE;
    huart1.Init.Mode = UART_MODE_TX_RX;
    huart1.Init.HwFlowCtl = UART_HWCONTROL_NONE;
    huart1.Init.OverSampling = UART_OVERSAMPLING_16;
    huart1.Init.OneBitSampling = UART_ONE_BIT_SAMPLE_DISABLE;
    huart1.Init.ClockPrescaler = UART_PRESCALER_DIV1;
    huart1.AdvancedInit.AdvFeatureInit = UART_ADVFEATURE_NO_INIT;
    if (HAL_UART_Init(&huart1) != HAL_OK)
    {
        Error_Handler();
    }
    if (HAL_UARTEx_SetTxFifoThreshold(&huart1, UART_TXFIFO_THRESHOLD_1_8) != HAL_OK)
    {
        Error_Handler();
    }
    if (HAL_UARTEx_SetRxFifoThreshold(&huart1, UART_RXFIFO_THRESHOLD_1_8) != HAL_OK)
    {
        Error_Handler();
    }
    if (HAL_UARTEx_DisableFifoMode(&huart1) != HAL_OK)
    {
        Error_Handler();
    }
}

static void MX_USART3_UART_Init(void)
{

    huart3.Instance = USART3;
    huart3.Init.BaudRate = 115200;
    huart3.Init.WordLength = UART_WORDLENGTH_8B;
    huart3.Init.StopBits = UART_STOPBITS_1;
    huart3.Init.Parity = UART_PARITY_NONE;
    huart3.Init.Mode = UART_MODE_TX_RX;
    huart3.Init.HwFlowCtl = UART_HWCONTROL_NONE;
    huart3.Init.OverSampling = UART_OVERSAMPLING_16;
    huart3.Init.OneBitSampling = UART_ONE_BIT_SAMPLE_DISABLE;
    huart3.Init.ClockPrescaler = UART_PRESCALER_DIV1;
    huart3.AdvancedInit.AdvFeatureInit = UART_ADVFEATURE_NO_INIT;
    if (HAL_UART_Init(&huart3) != HAL_OK)
    {
        Error_Handler();
    }
    if (HAL_UARTEx_SetTxFifoThreshold(&huart3, UART_TXFIFO_THRESHOLD_1_8) != HAL_OK)
    {
        Error_Handler();
    }
    if (HAL_UARTEx_SetRxFifoThreshold(&huart3, UART_RXFIFO_THRESHOLD_1_8) != HAL_OK)
    {
        Error_Handler();
    }
    if (HAL_UARTEx_DisableFifoMode(&huart3) != HAL_OK)
    {
        Error_Handler();
    }
}

static void MX_USB_OTG_HS_USB_Init(void)
{

}

static void MX_GPIO_Init(void)
{
    GPIO_InitTypeDef GPIO_InitStruct = {0};

    /* GPIO Ports Clock Enable */
    __HAL_RCC_GPIOB_CLK_ENABLE();
    __HAL_RCC_GPIOG_CLK_ENABLE();
    __HAL_RCC_GPIOD_CLK_ENABLE();
    __HAL_RCC_GPIOA_CLK_ENABLE();
    __HAL_RCC_GPIOE_CLK_ENABLE();
    __HAL_RCC_GPIOC_CLK_ENABLE();
    __HAL_RCC_GPIOH_CLK_ENABLE();
    __HAL_RCC_GPIOF_CLK_ENABLE();

    /*Configure GPIO pin Output Level */
    HAL_GPIO_WritePin(GPIOD, Detectn_Pin | LCD_DISP_Pin, GPIO_PIN_RESET);

    /*Configure GPIO pin Output Level */
    HAL_GPIO_WritePin(GPIOE, ARD_D8_Pin | STMOD_17_Pin | STMOD_19_Pin | STMOD_18_Pin, GPIO_PIN_RESET);

    /*Configure GPIO pin Output Level */
    HAL_GPIO_WritePin(GPIOG, LCD_BL_CTRL_Pin | ARD_D7_Pin | MEMS_LED_Pin | ARD_D4_Pin | ARD_D2_Pin, GPIO_PIN_RESET);

    /*Configure GPIO pin Output Level */
    HAL_GPIO_WritePin(GPIOC, USER_LED2_Pin | USER_LED1_Pin, GPIO_PIN_RESET);

    /*Configure GPIO pin Output Level */
    HAL_GPIO_WritePin(STMOD_20_GPIO_Port, STMOD_20_Pin, GPIO_PIN_RESET);

    /*Configure GPIO pin Output Level */
    HAL_GPIO_WritePin(GPIOH, LCD_RST_Pin | USB_FS_PWR_EN_Pin, GPIO_PIN_RESET);

    /*Configure GPIO pins : Detectn_Pin LCD_DISP_Pin */
    GPIO_InitStruct.Pin = Detectn_Pin | LCD_DISP_Pin;
    GPIO_InitStruct.Mode = GPIO_MODE_OUTPUT_PP;
    GPIO_InitStruct.Pull = GPIO_NOPULL;
    GPIO_InitStruct.Speed = GPIO_SPEED_FREQ_LOW;
    HAL_GPIO_Init(GPIOD, &GPIO_InitStruct);

    /*Configure GPIO pins : SAI4_D2_Pin SAI4_CK2_Pin */
    GPIO_InitStruct.Pin = SAI4_D2_Pin | SAI4_CK2_Pin;
    GPIO_InitStruct.Mode = GPIO_MODE_AF_PP;
    GPIO_InitStruct.Pull = GPIO_NOPULL;
    GPIO_InitStruct.Speed = GPIO_SPEED_FREQ_LOW;
    GPIO_InitStruct.Alternate = GPIO_AF10_SAI4;
    HAL_GPIO_Init(GPIOE, &GPIO_InitStruct);

    /*Configure GPIO pins : ARD_D8_Pin STMOD_17_Pin STMOD_19_Pin STMOD_18_Pin */
    GPIO_InitStruct.Pin = ARD_D8_Pin | STMOD_17_Pin | STMOD_19_Pin | STMOD_18_Pin;
    GPIO_InitStruct.Mode = GPIO_MODE_OUTPUT_PP;
    GPIO_InitStruct.Pull = GPIO_NOPULL;
    GPIO_InitStruct.Speed = GPIO_SPEED_FREQ_LOW;
    HAL_GPIO_Init(GPIOE, &GPIO_InitStruct);

    /*Configure GPIO pins : USB_FS_OVCR_Pin CTP_INT_Pin */
    GPIO_InitStruct.Pin = USB_FS_OVCR_Pin | CTP_INT_Pin;
    GPIO_InitStruct.Mode = GPIO_MODE_IT_RISING;
    GPIO_InitStruct.Pull = GPIO_NOPULL;
    HAL_GPIO_Init(GPIOG, &GPIO_InitStruct);

    /*Configure GPIO pin : Blue_button_B2_used_for_wakeup_Pin */
    GPIO_InitStruct.Pin = Blue_button_B2_used_for_wakeup_Pin;
    GPIO_InitStruct.Mode = GPIO_MODE_INPUT;
    GPIO_InitStruct.Pull = GPIO_NOPULL;
    HAL_GPIO_Init(Blue_button_B2_used_for_wakeup_GPIO_Port, &GPIO_InitStruct);

    /*Configure GPIO pin : USB_FS_ID_Pin */
    GPIO_InitStruct.Pin = USB_FS_ID_Pin;
    GPIO_InitStruct.Mode = GPIO_MODE_AF_PP;
    GPIO_InitStruct.Pull = GPIO_NOPULL;
    GPIO_InitStruct.Speed = GPIO_SPEED_FREQ_LOW;
    GPIO_InitStruct.Alternate = GPIO_AF10_OTG1_HS;
    HAL_GPIO_Init(USB_FS_ID_GPIO_Port, &GPIO_InitStruct);

    /*Configure GPIO pins : LCD_BL_CTRL_Pin ARD_D7_Pin MEMS_LED_Pin ARD_D4_Pin
                             ARD_D2_Pin */
    GPIO_InitStruct.Pin = LCD_BL_CTRL_Pin | ARD_D7_Pin | MEMS_LED_Pin | ARD_D4_Pin | ARD_D2_Pin;
    GPIO_InitStruct.Mode = GPIO_MODE_OUTPUT_PP;
    GPIO_InitStruct.Pull = GPIO_NOPULL;
    GPIO_InitStruct.Speed = GPIO_SPEED_FREQ_LOW;
    HAL_GPIO_Init(GPIOG, &GPIO_InitStruct);

    /*Configure GPIO pin : USB_FS_VBUS_Pin */
    GPIO_InitStruct.Pin = USB_FS_VBUS_Pin;
    GPIO_InitStruct.Mode = GPIO_MODE_INPUT;
    GPIO_InitStruct.Pull = GPIO_NOPULL;
    HAL_GPIO_Init(USB_FS_VBUS_GPIO_Port, &GPIO_InitStruct);

    /*Configure GPIO pin : uSD_Detect_Pin */
    GPIO_InitStruct.Pin = uSD_Detect_Pin;
    GPIO_InitStruct.Mode = GPIO_MODE_IT_RISING;
    GPIO_InitStruct.Pull = GPIO_NOPULL;
    HAL_GPIO_Init(uSD_Detect_GPIO_Port, &GPIO_InitStruct);

    /*Configure GPIO pins : USER_LED2_Pin USER_LED1_Pin */
    GPIO_InitStruct.Pin = USER_LED2_Pin | USER_LED1_Pin;
    GPIO_InitStruct.Mode = GPIO_MODE_OUTPUT_PP;
    GPIO_InitStruct.Pull = GPIO_NOPULL;
    GPIO_InitStruct.Speed = GPIO_SPEED_FREQ_LOW;
    HAL_GPIO_Init(GPIOC, &GPIO_InitStruct);

    /*Configure GPIO pin : SPI5_MISO_Pin */
    GPIO_InitStruct.Pin = SPI5_MISO_Pin;
    GPIO_InitStruct.Mode = GPIO_MODE_AF_PP;
    GPIO_InitStruct.Pull = GPIO_NOPULL;
    GPIO_InitStruct.Speed = GPIO_SPEED_FREQ_LOW;
    GPIO_InitStruct.Alternate = GPIO_AF5_SPI5;
    HAL_GPIO_Init(SPI5_MISO_GPIO_Port, &GPIO_InitStruct);

    /*Configure GPIO pin : SPI5_MOSI_Pin */
    GPIO_InitStruct.Pin = SPI5_MOSI_Pin;
    GPIO_InitStruct.Mode = GPIO_MODE_AF_PP;
    GPIO_InitStruct.Pull = GPIO_NOPULL;
    GPIO_InitStruct.Speed = GPIO_SPEED_FREQ_LOW;
    GPIO_InitStruct.Alternate = GPIO_AF5_SPI5;
    HAL_GPIO_Init(SPI5_MOSI_GPIO_Port, &GPIO_InitStruct);

    /*Configure GPIO pin : Audio_Int_Pin */
    GPIO_InitStruct.Pin = Audio_Int_Pin;
    GPIO_InitStruct.Mode = GPIO_MODE_IT_RISING;
    GPIO_InitStruct.Pull = GPIO_NOPULL;
    HAL_GPIO_Init(Audio_Int_GPIO_Port, &GPIO_InitStruct);

    /*Configure GPIO pin : STMOD_20_Pin */
    GPIO_InitStruct.Pin = STMOD_20_Pin;
    GPIO_InitStruct.Mode = GPIO_MODE_OUTPUT_PP;
    GPIO_InitStruct.Pull = GPIO_NOPULL;
    GPIO_InitStruct.Speed = GPIO_SPEED_FREQ_LOW;
    HAL_GPIO_Init(STMOD_20_GPIO_Port, &GPIO_InitStruct);

    /*Configure GPIO pin : STMOD_11_INT_Pin */
    GPIO_InitStruct.Pin = STMOD_11_INT_Pin;
    GPIO_InitStruct.Mode = GPIO_MODE_IT_RISING;
    GPIO_InitStruct.Pull = GPIO_NOPULL;
    HAL_GPIO_Init(STMOD_11_INT_GPIO_Port, &GPIO_InitStruct);

    /*Configure GPIO pins : LCD_RST_Pin USB_FS_PWR_EN_Pin */
    GPIO_InitStruct.Pin = LCD_RST_Pin | USB_FS_PWR_EN_Pin;
    GPIO_InitStruct.Mode = GPIO_MODE_OUTPUT_PP;
    GPIO_InitStruct.Pull = GPIO_NOPULL;
    GPIO_InitStruct.Speed = GPIO_SPEED_FREQ_LOW;
    HAL_GPIO_Init(GPIOH, &GPIO_InitStruct);

}

void Error_Handler(void)
{
    __disable_irq();
    while (1)
    {
    }
}
